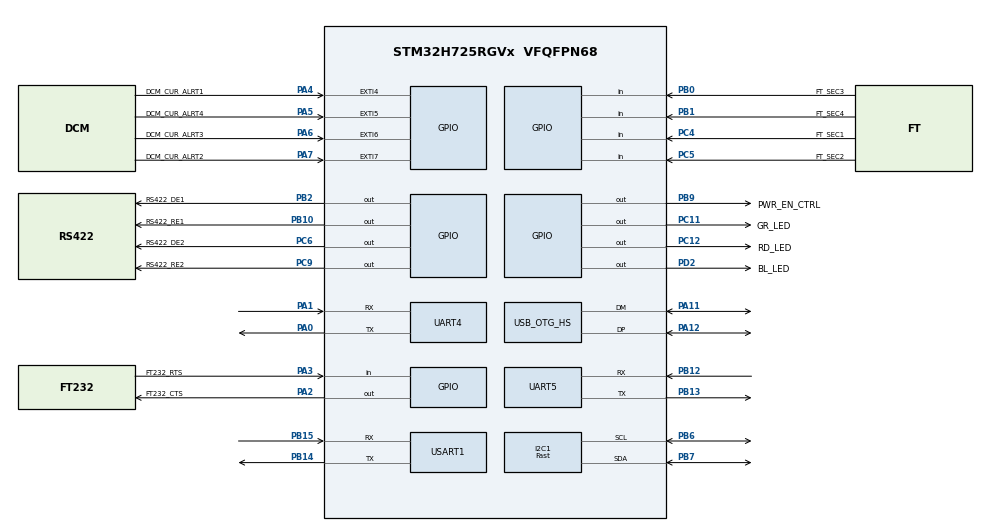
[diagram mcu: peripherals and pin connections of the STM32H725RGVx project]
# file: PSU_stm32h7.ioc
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CORTEX_M7.CPU_DCache=Disabled
CORTEX_M7.CPU_ICache=Enabled
CORTEX_M7.default_mode_Activation=1
Dma.I2C1_RX.0.Direction=DMA_PERIPH_TO_MEMORY
Dma.I2C1_RX.0.EventEnable=DISABLE
Dma.I2C1_RX.0.FIFOMode=DMA_FIFOMODE_DISABLE
Dma.I2C1_RX.0.Instance=DMA1_Stream0
Dma.I2C1_RX.0.MemDataAlignment=DMA_MDATAALIGN_BYTE
Dma.I2C1_RX.0.MemInc=DMA_MINC_ENABLE
Dma.I2C1_RX.0.Mode=DMA_NORMAL
Dma.I2C1_RX.0.PeriphDataAlignment=DMA_PDATAALIGN_BYTE
Dma.I2C1_RX.0.PeriphInc=DMA_PINC_DISABLE
Dma.I2C1_RX.0.Polarity=HAL_DMAMUX_REQ_GEN_RISING
Dma.I2C1_RX.0.Priority=DMA_PRIORITY_MEDIUM
Dma.I2C1_RX.0.RequestNumber=1
Dma.I2C1_RX.0.SignalID=NONE
Dma.I2C1_RX.0.SyncEnable=DISABLE
Dma.I2C1_RX.0.SyncPolarity=HAL_DMAMUX_SYNC_NO_EVENT
Dma.I2C1_RX.0.SyncRequestNumber=1
Dma.I2C1_RX.0.SyncSignalID=NONE
Dma.I2C1_TX.1.Direction=DMA_MEMORY_TO_PERIPH
Dma.I2C1_TX.1.EventEnable=DISABLE
Dma.I2C1_TX.1.FIFOMode=DMA_FIFOMODE_DISABLE
Dma.I2C1_TX.1.Instance=DMA1_Stream1
Dma.I2C1_TX.1.MemDataAlignment=DMA_MDATAALIGN_BYTE
Dma.I2C1_TX.1.MemInc=DMA_MINC_ENABLE
Dma.I2C1_TX.1.Mode=DMA_NORMAL
Dma.I2C1_TX.1.PeriphDataAlignment=DMA_PDATAALIGN_BYTE
Dma.I2C1_TX.1.PeriphInc=DMA_PINC_DISABLE
Dma.I2C1_TX.1.Polarity=HAL_DMAMUX_REQ_GEN_RISING
Dma.I2C1_TX.1.Priority=DMA_PRIORITY_MEDIUM
Dma.I2C1_TX.1.RequestNumber=1
Dma.I2C1_TX.1.SignalID=NONE
Dma.I2C1_TX.1.SyncEnable=DISABLE
Dma.I2C1_TX.1.SyncPolarity=HAL_DMAMUX_SYNC_NO_EVENT
Dma.I2C1_TX.1.SyncRequestNumber=1
Dma.I2C1_TX.1.SyncSignalID=NONE
Dma.Request0=I2C1_RX
Dma.Request1=I2C1_TX
Dma.Request2=USART1_TX
Dma.Request3=UART5_TX
Dma.Request4=UART4_TX
Dma.Request5=USART1_RX
Dma.Request6=UART4_RX
Dma.Request7=UART5_RX
Dma.UART4_RX.6.Direction=DMA_PERIPH_TO_MEMORY
Dma.UART4_RX.6.EventEnable=DISABLE
Dma.UART4_RX.6.FIFOMode=DMA_FIFOMODE_DISABLE
Dma.UART4_RX.6.Instance=DMA1_Stream6
Dma.UART4_RX.6.MemDataAlignment=DMA_MDATAALIGN_BYTE
Dma.UART4_RX.6.MemInc=DMA_MINC_ENABLE
Dma.UART4_RX.6.Mode=DMA_CIRCULAR
Dma.UART4_RX.6.PeriphDataAlignment=DMA_PDATAALIGN_BYTE
Dma.UART4_RX.6.PeriphInc=DMA_PINC_DISABLE
Dma.UART4_RX.6.Polarity=HAL_DMAMUX_REQ_GEN_RISING
Dma.UART4_RX.6.Priority=DMA_PRIORITY_LOW
Dma.UART4_RX.6.RequestNumber=1
Dma.UART4_RX.6.SignalID=NONE
Dma.UART4_RX.6.SyncEnable=DISABLE
Dma.UART4_RX.6.SyncPolarity=HAL_DMAMUX_SYNC_NO_EVENT
Dma.UART4_RX.6.SyncRequestNumber=1
Dma.UART4_RX.6.SyncSignalID=NONE
Dma.UART4_TX.4.Direction=DMA_MEMORY_TO_PERIPH
Dma.UART4_TX.4.EventEnable=DISABLE
Dma.UART4_TX.4.FIFOMode=DMA_FIFOMODE_DISABLE
Dma.UART4_TX.4.Instance=DMA1_Stream4
Dma.UART4_TX.4.MemDataAlignment=DMA_MDATAALIGN_BYTE
Dma.UART4_TX.4.MemInc=DMA_MINC_ENABLE
Dma.UART4_TX.4.Mode=DMA_NORMAL
Dma.UART4_TX.4.PeriphDataAlignment=DMA_PDATAALIGN_BYTE
Dma.UART4_TX.4.PeriphInc=DMA_PINC_DISABLE
Dma.UART4_TX.4.Polarity=HAL_DMAMUX_REQ_GEN_RISING
Dma.UART4_TX.4.Priority=DMA_PRIORITY_LOW
Dma.UART4_TX.4.RequestNumber=1
Dma.UART4_TX.4.SignalID=NONE
Dma.UART4_TX.4.SyncEnable=DISABLE
Dma.UART4_TX.4.SyncPolarity=HAL_DMAMUX_SYNC_NO_EVENT
Dma.UART4_TX.4.SyncRequestNumber=1
Dma.UART4_TX.4.SyncSignalID=NONE
Dma.UART5_RX.7.Direction=DMA_PERIPH_TO_MEMORY
Dma.UART5_RX.7.EventEnable=DISABLE
Dma.UART5_RX.7.FIFOMode=DMA_FIFOMODE_DISABLE
Dma.UART5_RX.7.Instance=DMA1_Stream7
Dma.UART5_RX.7.MemDataAlignment=DMA_MDATAALIGN_BYTE
Dma.UART5_RX.7.MemInc=DMA_MINC_ENABLE
Dma.UART5_RX.7.Mode=DMA_CIRCULAR
Dma.UART5_RX.7.PeriphDataAlignment=DMA_PDATAALIGN_BYTE
Dma.UART5_RX.7.PeriphInc=DMA_PINC_DISABLE
Dma.UART5_RX.7.Polarity=HAL_DMAMUX_REQ_GEN_RISING
Dma.UART5_RX.7.Priority=DMA_PRIORITY_LOW
Dma.UART5_RX.7.RequestNumber=1
Dma.UART5_RX.7.SignalID=NONE
Dma.UART5_RX.7.SyncEnable=DISABLE
Dma.UART5_RX.7.SyncPolarity=HAL_DMAMUX_SYNC_NO_EVENT
Dma.UART5_RX.7.SyncRequestNumber=1
Dma.UART5_RX.7.SyncSignalID=NONE
Dma.UART5_TX.3.Direction=DMA_MEMORY_TO_PERIPH
Dma.UART5_TX.3.EventEnable=DISABLE
Dma.UART5_TX.3.FIFOMode=DMA_FIFOMODE_DISABLE
Dma.UART5_TX.3.Instance=DMA1_Stream3
Dma.UART5_TX.3.MemDataAlignment=DMA_MDATAALIGN_BYTE
Dma.UART5_TX.3.MemInc=DMA_MINC_ENABLE
Dma.UART5_TX.3.Mode=DMA_NORMAL
Dma.UART5_TX.3.PeriphDataAlignment=DMA_PDATAALIGN_BYTE
Dma.UART5_TX.3.PeriphInc=DMA_PINC_DISABLE
Dma.UART5_TX.3.Polarity=HAL_DMAMUX_REQ_GEN_RISING
Dma.UART5_TX.3.Priority=DMA_PRIORITY_LOW
Dma.UART5_TX.3.RequestNumber=1
Dma.UART5_TX.3.SignalID=NONE
Dma.UART5_TX.3.SyncEnable=DISABLE
Dma.UART5_TX.3.SyncPolarity=HAL_DMAMUX_SYNC_NO_EVENT
Dma.UART5_TX.3.SyncRequestNumber=1
Dma.UART5_TX.3.SyncSignalID=NONE
Dma.USART1_RX.5.Direction=DMA_PERIPH_TO_MEMORY
Dma.USART1_RX.5.EventEnable=DISABLE
Dma.USART1_RX.5.FIFOMode=DMA_FIFOMODE_DISABLE
Dma.USART1_RX.5.Instance=DMA1_Stream5
Dma.USART1_RX.5.MemDataAlignment=DMA_MDATAALIGN_BYTE
Dma.USART1_RX.5.MemInc=DMA_MINC_ENABLE
Dma.USART1_RX.5.Mode=DMA_CIRCULAR
Dma.USART1_RX.5.PeriphDataAlignment=DMA_PDATAALIGN_BYTE
Dma.USART1_RX.5.PeriphInc=DMA_PINC_DISABLE
Dma.USART1_RX.5.Polarity=HAL_DMAMUX_REQ_GEN_RISING
Dma.USART1_RX.5.Priority=DMA_PRIORITY_LOW
Dma.USART1_RX.5.RequestNumber=1
Dma.USART1_RX.5.SignalID=NONE
Dma.USART1_RX.5.SyncEnable=DISABLE
Dma.USART1_RX.5.SyncPolarity=HAL_DMAMUX_SYNC_NO_EVENT
Dma.USART1_RX.5.SyncRequestNumber=1
Dma.USART1_RX.5.SyncSignalID=NONE
Dma.USART1_TX.2.Direction=DMA_MEMORY_TO_PERIPH
Dma.USART1_TX.2.EventEnable=DISABLE
Dma.USART1_TX.2.FIFOMode=DMA_FIFOMODE_DISABLE
Dma.USART1_TX.2.Instance=DMA1_Stream2
Dma.USART1_TX.2.MemDataAlignment=DMA_MDATAALIGN_BYTE
Dma.USART1_TX.2.MemInc=DMA_MINC_ENABLE
Dma.USART1_TX.2.Mode=DMA_NORMAL
Dma.USART1_TX.2.PeriphDataAlignment=DMA_PDATAALIGN_BYTE
Dma.USART1_TX.2.PeriphInc=DMA_PINC_DISABLE
Dma.USART1_TX.2.Polarity=HAL_DMAMUX_REQ_GEN_RISING
Dma.USART1_TX.2.Priority=DMA_PRIORITY_LOW
Dma.USART1_TX.2.RequestNumber=1
Dma.USART1_TX.2.SignalID=NONE
Dma.USART1_TX.2.SyncEnable=DISABLE
Dma.USART1_TX.2.SyncPolarity=HAL_DMAMUX_SYNC_NO_EVENT
Dma.USART1_TX.2.SyncRequestNumber=1
Dma.USART1_TX.2.SyncSignalID=NONE
I2C1.I2C_Coeff_DF=2
I2C1.I2C_Fall_Time=10
I2C1.I2C_Rise_Time=100
I2C1.I2C_Speed_Mode=I2C_Fast
I2C1.Timing=0x00C01F6A
Mcu.Family=STM32H7
Mcu.Name=STM32H725RGVx
Mcu.Package=VFQFPN68
NVIC.DMA1_Stream0_IRQn=true\:3\:0\:true\:false\:true\:false\:true\:true
NVIC.DMA1_Stream1_IRQn=true\:3\:0\:true\:false\:true\:false\:true\:true
NVIC.DMA1_Stream2_IRQn=true\:5\:0\:true\:false\:true\:false\:true\:true
NVIC.DMA1_Stream3_IRQn=true\:5\:0\:true\:false\:true\:false\:true\:true
NVIC.DMA1_Stream4_IRQn=true\:5\:0\:true\:false\:true\:false\:true\:true
NVIC.DMA1_Stream5_IRQn=true\:6\:0\:true\:false\:true\:false\:true\:true
NVIC.DMA1_Stream6_IRQn=true\:6\:0\:true\:false\:true\:false\:true\:true
NVIC.DMA1_Stream7_IRQn=true\:6\:0\:true\:false\:true\:false\:true\:true
NVIC.EXTI4_IRQn=true\:4\:0\:true\:false\:true\:true\:true\:true
NVIC.EXTI9_5_IRQn=true\:4\:0\:true\:false\:true\:true\:true\:true
NVIC.I2C1_ER_IRQn=true\:3\:0\:true\:false\:true\:true\:true\:true
NVIC.I2C1_EV_IRQn=true\:3\:0\:true\:false\:true\:true\:true\:true
NVIC.OTG_HS_IRQn=true\:6\:0\:true\:false\:true\:false\:true\:true
NVIC.PriorityGroup=NVIC_PRIORITYGROUP_4
NVIC.UART4_IRQn=true\:5\:0\:true\:false\:true\:false\:true\:true
NVIC.UART5_IRQn=true\:5\:0\:true\:false\:true\:false\:true\:true
NVIC.USART1_IRQn=true\:5\:0\:true\:false\:true\:false\:true\:true
PA0.Mode=Asynchronous
PA0.Signal=UART4_TX
PA1.Mode=Asynchronous
PA1.Signal=UART4_RX
PA11.Mode=Device_Only_FS
PA11.Signal=USB_OTG_HS_DM
PA12.Mode=Device_Only_FS
PA12.Signal=USB_OTG_HS_DP
PA13(JTMS/SWDIO).Mode=Serial_Wire
PA13(JTMS/SWDIO).Signal=DEBUG_JTMS-SWDIO
PA14(JTCK/SWCLK).Mode=Serial_Wire
PA14(JTCK/SWCLK).Signal=DEBUG_JTCK-SWCLK
PA2.GPIO_Label=FT232_CTS
PA2.Signal=GPIO_Output
PA3.GPIO_Label=FT232_RTS
PA3.GPIO_PuPd=GPIO_PULLUP
PA3.Signal=GPIO_Input
PA4.GPIO_Label=DCM_CUR_ALRT1
PA4.GPIO_ModeDefaultEXTI=GPIO_MODE_IT_FALLING
PA4.GPIO_PuPd=GPIO_PULLUP
PA4.Signal=GPXTI4
PA5.GPIO_Label=DCM_CUR_ALRT4
PA5.GPIO_ModeDefaultEXTI=GPIO_MODE_IT_FALLING
PA5.GPIO_PuPd=GPIO_PULLUP
PA5.Signal=GPXTI5
PA6.GPIO_Label=DCM_CUR_ALRT3
PA6.GPIO_ModeDefaultEXTI=GPIO_MODE_IT_FALLING
PA6.GPIO_PuPd=GPIO_PULLUP
PA6.Signal=GPXTI6
PA7.GPIO_Label=DCM_CUR_ALRT2
PA7.GPIO_ModeDefaultEXTI=GPIO_MODE_IT_FALLING
PA7.GPIO_PuPd=GPIO_PULLUP
PA7.Signal=GPXTI7
PB0.GPIO_Label=FT_SEC3
PB0.Signal=GPIO_Input
PB1.GPIO_Label=FT_SEC4
PB1.Signal=GPIO_Input
PB10.GPIO_Label=RS422_RE1
PB10.GPIO_ModeDefaultOutputPP=GPIO_MODE_OUTPUT_PP
PB10.GPIO_PuPd=GPIO_NOPULL
PB10.Signal=GPIO_Output
PB12.Mode=Asynchronous
PB12.Signal=UART5_RX
PB13.Mode=Asynchronous
PB13.Signal=UART5_TX
PB14.Mode=Asynchronous
PB14.Signal=USART1_TX
PB15.Mode=Asynchronous
PB15.Signal=USART1_RX
PB2.GPIO_Label=RS422_DE1
PB2.Signal=GPIO_Output
PB6.Mode=I2C
PB6.Signal=I2C1_SCL
PB7.Mode=I2C
PB7.Signal=I2C1_SDA
PB9.GPIO_Label=PWR_EN_CTRL
PB9.Signal=GPIO_Output
PC11.GPIO_Label=GR_LED
PC11.Signal=GPIO_Output
PC12.GPIO_Label=RD_LED
PC12.Signal=GPIO_Output
PC14-OSC32_IN.Mode=LSE-External-Oscillator
PC14-OSC32_IN.Signal=RCC_OSC32_IN
PC15-OSC32_OUT.Mode=LSE-External-Oscillator
PC15-OSC32_OUT.Signal=RCC_OSC32_OUT
PC4.GPIO_Label=FT_SEC1
PC4.Signal=GPIO_Input
PC5.GPIO_Label=FT_SEC2
PC5.Signal=GPIO_Input
PC6.GPIO_Label=RS422_DE2
PC6.Signal=GPIO_Output
PC9.GPIO_Label=RS422_RE2
PC9.Signal=GPIO_Output
PD2.GPIO_Label=BL_LED
PD2.Signal=GPIO_Output
PH0-OSC_IN.Mode=HSE-External-Clock-Source
PH0-OSC_IN.Signal=RCC_OSC_IN
ProjectManager.HeapSize=0x200
ProjectManager.StackSize=0x400
ProjectManager.TargetToolchain=STM32CubeIDE
RCC.ADCFreq_Value=50390625
RCC.APB1Freq_Value=50000000
RCC.APB2Freq_Value=50000000
RCC.APB3Freq_Value=50000000
RCC.APB4Freq_Value=50000000
RCC.CortexFreq_Value=200000000
RCC.D1PPRE=RCC_APB3_DIV2
RCC.D2PPRE1=RCC_APB1_DIV2
RCC.D2PPRE2=RCC_APB2_DIV2
RCC.D3PPRE=RCC_APB4_DIV2
RCC.DIVM1=5
RCC.DIVN1=40
RCC.DIVP1=1
RCC.DIVQ1=5
RCC.DIVR1=5
RCC.HCLKFreq_Value=100000000
RCC.HPRE=RCC_HCLK_DIV2
RCC.I2C123CLockSelection=RCC_I2C1235CLKSOURCE_HSI
RCC.PLLFRACN=0
RCC.PLLSourceVirtual=RCC_PLLSOURCE_HSE
RCC.SYSCLKFreq_VALUE=200000000
RCC.SYSCLKSource=RCC_SYSCLKSOURCE_PLLCLK
RCC.USBCLockSelection=RCC_USBCLKSOURCE_HSI48
RCC.USBFreq_Value=48000000
USART1.VirtualMode-Asynchronous=VM_ASYNC
USB_DEVICE.CLASS_NAME_HS=CDC
USB_DEVICE.VirtualMode=Cdc
USB_DEVICE.VirtualModeHS=Cdc_HS
USB_OTG_HS.VirtualMode=Device_Only_FS
VP_MEMORYMAP_VS_MEMORYMAP.Mode=CurAppReg
VP_USB_DEVICE_VS_USB_DEVICE_CDC_HS.Mode=CDC_HS
board=custom

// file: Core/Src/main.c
/* USER CODE BEGIN Header */
/**
  ******************************************************************************
  * @file           : main.c
  * @brief          : Main program body
  ******************************************************************************
  * @attention
  *
  * Copyright (c) 2026 STMicroelectronics.
  * All rights reserved.
  *
  * This software is licensed under terms that can be found in the LICENSE file
  * in the root directory of this software component.
  * If no LICENSE file comes with this software, it is provided AS-IS.
  *
  ******************************************************************************
  */
/* USER CODE END Header */
#include "main.h"
#include "usb_device.h"

/* USER CODE BEGIN Includes */
#include "app_main.h"
#include "safety.h"
/* USER CODE END Includes */

I2C_HandleTypeDef hi2c1;
DMA_HandleTypeDef hdma_i2c1_rx;
DMA_HandleTypeDef hdma_i2c1_tx;

UART_HandleTypeDef huart4;
UART_HandleTypeDef huart5;
UART_HandleTypeDef huart1;
DMA_HandleTypeDef hdma_uart4_tx;
DMA_HandleTypeDef hdma_uart4_rx;
DMA_HandleTypeDef hdma_uart5_tx;
DMA_HandleTypeDef hdma_uart5_rx;
DMA_HandleTypeDef hdma_usart1_tx;
DMA_HandleTypeDef hdma_usart1_rx;

void SystemClock_Config(void);
static void MPU_Config(void);
static void MX_GPIO_Init(void);
static void MX_DMA_Init(void);
static void MX_UART4_Init(void);
static void MX_I2C1_Init(void);
static void MX_UART5_Init(void);
static void MX_USART1_UART_Init(void);

int main(void)
{

  /* USER CODE BEGIN 1 */
	__enable_irq();

	  extern uint32_t g_pfnVectors;
	  SCB->VTOR = (uint32_t)&g_pfnVectors;
	  __DSB();
	  __ISB();
  /* USER CODE END 1 */

  /* MPU Configuration--------------------------------------------------------*/
  MPU_Config();

  /* Enable the CPU Cache */

  /* Enable I-Cache---------------------------------------------------------*/
  SCB_EnableICache();

  /* MCU Configuration--------------------------------------------------------*/

  /* Reset of all peripherals, Initializes the Flash interface and the Systick. */
  HAL_Init();

  /* USER CODE BEGIN Init */

  // Enable clock cho vung D2 SRAM
  __HAL_RCC_D2SRAM1_CLK_ENABLE();
  __HAL_RCC_D2SRAM2_CLK_ENABLE();

  /* USER CODE END Init */

  /* Configure the system clock */
  SystemClock_Config();

  /* USER CODE BEGIN SysInit */

  App_EarlyInit();

  /* USER CODE END SysInit */

  /* Initialize all configured peripherals */
  MX_GPIO_Init();
  MX_DMA_Init();
  MX_UART4_Init();
  MX_I2C1_Init();
  MX_UART5_Init();
  MX_USART1_UART_Init();
  MX_USB_DEVICE_Init();
  /* USER CODE BEGIN 2 */

  App_Init();

  /* USER CODE END 2 */

  /* Infinite loop */
  /* USER CODE BEGIN WHILE */
  while (1)
  {

	  App_Loop();

    /* USER CODE END WHILE */

  }
}

void SystemClock_Config(void)
{
  RCC_OscInitTypeDef RCC_OscInitStruct = {0};
  RCC_ClkInitTypeDef RCC_ClkInitStruct = {0};

  /** Supply configuration update enable
  */
  HAL_PWREx_ConfigSupply(PWR_DIRECT_SMPS_SUPPLY);

  /** Configure the main internal regulator output voltage
  */
  __HAL_PWR_VOLTAGESCALING_CONFIG(PWR_REGULATOR_VOLTAGE_SCALE2);

  while(!__HAL_PWR_GET_FLAG(PWR_FLAG_VOSRDY)) {}

  /** Initializes the RCC Oscillators according to the specified parameters
  * in the RCC_OscInitTypeDef structure.
  */
  RCC_OscInitStruct.OscillatorType = RCC_OSCILLATORTYPE_HSI48|RCC_OSCILLATORTYPE_HSI
                              |RCC_OSCILLATORTYPE_HSE;
  RCC_OscInitStruct.HSEState = RCC_HSE_BYPASS;
  RCC_OscInitStruct.HSIState = RCC_HSI_DIV1;
  RCC_OscInitStruct.HSICalibrationValue = 64;
  RCC_OscInitStruct.HSI48State = RCC_HSI48_ON;
  RCC_OscInitStruct.PLL.PLLState = RCC_PLL_ON;
  RCC_OscInitStruct.PLL.PLLSource = RCC_PLLSOURCE_HSE;
  RCC_OscInitStruct.PLL.PLLM = 5;
  RCC_OscInitStruct.PLL.PLLN = 40;
  RCC_OscInitStruct.PLL.PLLP = 1;
  RCC_OscInitStruct.PLL.PLLQ = 5;
  RCC_OscInitStruct.PLL.PLLR = 5;
  RCC_OscInitStruct.PLL.PLLRGE = RCC_PLL1VCIRANGE_2;
  RCC_OscInitStruct.PLL.PLLVCOSEL = RCC_PLL1VCOWIDE;
  RCC_OscInitStruct.PLL.PLLFRACN = 0;
  if (HAL_RCC_OscConfig(&RCC_OscInitStruct) != HAL_OK)
  {
    Error_Handler();
  }

  /** Initializes the CPU, AHB and APB buses clocks
  */
  RCC_ClkInitStruct.ClockType = RCC_CLOCKTYPE_HCLK|RCC_CLOCKTYPE_SYSCLK
                              |RCC_CLOCKTYPE_PCLK1|RCC_CLOCKTYPE_PCLK2
                              |RCC_CLOCKTYPE_D3PCLK1|RCC_CLOCKTYPE_D1PCLK1;
  RCC_ClkInitStruct.SYSCLKSource = RCC_SYSCLKSOURCE_PLLCLK;
  RCC_ClkInitStruct.SYSCLKDivider = RCC_SYSCLK_DIV1;
  RCC_ClkInitStruct.AHBCLKDivider = RCC_HCLK_DIV2;
  RCC_ClkInitStruct.APB3CLKDivider = RCC_APB3_DIV2;
  RCC_ClkInitStruct.APB1CLKDivider = RCC_APB1_DIV2;
  RCC_ClkInitStruct.APB2CLKDivider = RCC_APB2_DIV2;
  RCC_ClkInitStruct.APB4CLKDivider = RCC_APB4_DIV2;

  if (HAL_RCC_ClockConfig(&RCC_ClkInitStruct, FLASH_LATENCY_1) != HAL_OK)
  {
    Error_Handler();
  }
}

static void MX_I2C1_Init(void)
{

  hi2c1.Instance = I2C1;
  hi2c1.Init.Timing = 0x00C01F6A;
  hi2c1.Init.OwnAddress1 = 0;
  hi2c1.Init.AddressingMode = I2C_ADDRESSINGMODE_7BIT;
  hi2c1.Init.DualAddressMode = I2C_DUALADDRESS_DISABLE;
  hi2c1.Init.OwnAddress2 = 0;
  hi2c1.Init.OwnAddress2Masks = I2C_OA2_NOMASK;
  hi2c1.Init.GeneralCallMode = I2C_GENERALCALL_DISABLE;
  hi2c1.Init.NoStretchMode = I2C_NOSTRETCH_DISABLE;
  if (HAL_I2C_Init(&hi2c1) != HAL_OK)
  {
    Error_Handler();
  }

  /** Configure Analogue filter
  */
  if (HAL_I2CEx_ConfigAnalogFilter(&hi2c1, I2C_ANALOGFILTER_ENABLE) != HAL_OK)
  {
    Error_Handler();
  }

  /** Configure Digital filter
  */
  if (HAL_I2CEx_ConfigDigitalFilter(&hi2c1, 2) != HAL_OK)
  {
    Error_Handler();
  }

}

static void MX_UART4_Init(void)
{

  huart4.Instance = UART4;
  huart4.Init.BaudRate = 115200;
  huart4.Init.WordLength = UART_WORDLENGTH_8B;
  huart4.Init.StopBits = UART_STOPBITS_1;
  huart4.Init.Parity = UART_PARITY_NONE;
  huart4.Init.Mode = UART_MODE_TX_RX;
  huart4.Init.HwFlowCtl = UART_HWCONTROL_NONE;
  huart4.Init.OverSampling = UART_OVERSAMPLING_16;
  huart4.Init.OneBitSampling = UART_ONE_BIT_SAMPLE_DISABLE;
  huart4.Init.ClockPrescaler = UART_PRESCALER_DIV1;
  huart4.AdvancedInit.AdvFeatureInit = UART_ADVFEATURE_NO_INIT;
  if (HAL_UART_Init(&huart4) != HAL_OK)
  {
    Error_Handler();
  }
  if (HAL_UARTEx_SetTxFifoThreshold(&huart4, UART_TXFIFO_THRESHOLD_1_8) != HAL_OK)
  {
    Error_Handler();
  }
  if (HAL_UARTEx_SetRxFifoThreshold(&huart4, UART_RXFIFO_THRESHOLD_1_8) != HAL_OK)
  {
    Error_Handler();
  }
  if (HAL_UARTEx_DisableFifoMode(&huart4) != HAL_OK)
  {
    Error_Handler();
  }

}

static void MX_UART5_Init(void)
{

  huart5.Instance = UART5;
  huart5.Init.BaudRate = 115200;
  huart5.Init.WordLength = UART_WORDLENGTH_8B;
  huart5.Init.StopBits = UART_STOPBITS_1;
  huart5.Init.Parity = UART_PARITY_NONE;
  huart5.Init.Mode = UART_MODE_TX_RX;
  huart5.Init.HwFlowCtl = UART_HWCONTROL_NONE;
  huart5.Init.OverSampling = UART_OVERSAMPLING_16;
  huart5.Init.OneBitSampling = UART_ONE_BIT_SAMPLE_DISABLE;
  huart5.Init.ClockPrescaler = UART_PRESCALER_DIV1;
  huart5.AdvancedInit.AdvFeatureInit = UART_ADVFEATURE_NO_INIT;
  if (HAL_UART_Init(&huart5) != HAL_OK)
  {
    Error_Handler();
  }
  if (HAL_UARTEx_SetTxFifoThreshold(&huart5, UART_TXFIFO_THRESHOLD_1_8) != HAL_OK)
  {
    Error_Handler();
  }
  if (HAL_UARTEx_SetRxFifoThreshold(&huart5, UART_RXFIFO_THRESHOLD_1_8) != HAL_OK)
  {
    Error_Handler();
  }
  if (HAL_UARTEx_DisableFifoMode(&huart5) != HAL_OK)
  {
    Error_Handler();
  }

}

static void MX_USART1_UART_Init(void)
{

  huart1.Instance = USART1;
  huart1.Init.BaudRate = 115200;
  huart1.Init.WordLength = UART_WORDLENGTH_8B;
  huart1.Init.StopBits = UART_STOPBITS_1;
  huart1.Init.Parity = UART_PARITY_NONE;
  huart1.Init.Mode = UART_MODE_TX_RX;
  huart1.Init.HwFlowCtl = UART_HWCONTROL_NONE;
  huart1.Init.OverSampling = UART_OVERSAMPLING_16;
  huart1.Init.OneBitSampling = UART_ONE_BIT_SAMPLE_DISABLE;
  huart1.Init.ClockPrescaler = UART_PRESCALER_DIV1;
  huart1.AdvancedInit.AdvFeatureInit = UART_ADVFEATURE_NO_INIT;
  if (HAL_UART_Init(&huart1) != HAL_OK)
  {
    Error_Handler();
  }
  if (HAL_UARTEx_SetTxFifoThreshold(&huart1, UART_TXFIFO_THRESHOLD_1_8) != HAL_OK)
  {
    Error_Handler();
  }
  if (HAL_UARTEx_SetRxFifoThreshold(&huart1, UART_RXFIFO_THRESHOLD_1_8) != HAL_OK)
  {
    Error_Handler();
  }
  if (HAL_UARTEx_DisableFifoMode(&huart1) != HAL_OK)
  {
    Error_Handler();
  }

}

static void MX_DMA_Init(void)
{

  /* DMA controller clock enable */
  __HAL_RCC_DMA1_CLK_ENABLE();

  /* DMA interrupt init */
  /* DMA1_Stream0_IRQn interrupt configuration */
  HAL_NVIC_SetPriority(DMA1_Stream0_IRQn, 3, 0);
  HAL_NVIC_EnableIRQ(DMA1_Stream0_IRQn);
  /* DMA1_Stream1_IRQn interrupt configuration */
  HAL_NVIC_SetPriority(DMA1_Stream1_IRQn, 3, 0);
  HAL_NVIC_EnableIRQ(DMA1_Stream1_IRQn);
  /* DMA1_Stream2_IRQn interrupt configuration */
  HAL_NVIC_SetPriority(DMA1_Stream2_IRQn, 5, 0);
  HAL_NVIC_EnableIRQ(DMA1_Stream2_IRQn);
  /* DMA1_Stream3_IRQn interrupt configuration */
  HAL_NVIC_SetPriority(DMA1_Stream3_IRQn, 5, 0);
  HAL_NVIC_EnableIRQ(DMA1_Stream3_IRQn);
  /* DMA1_Stream4_IRQn interrupt configuration */
  HAL_NVIC_SetPriority(DMA1_Stream4_IRQn, 5, 0);
  HAL_NVIC_EnableIRQ(DMA1_Stream4_IRQn);
  /* DMA1_Stream5_IRQn interrupt configuration */
  HAL_NVIC_SetPriority(DMA1_Stream5_IRQn, 6, 0);
  HAL_NVIC_EnableIRQ(DMA1_Stream5_IRQn);
  /* DMA1_Stream6_IRQn interrupt configuration */
  HAL_NVIC_SetPriority(DMA1_Stream6_IRQn, 6, 0);
  HAL_NVIC_EnableIRQ(DMA1_Stream6_IRQn);
  /* DMA1_Stream7_IRQn interrupt configuration */
  HAL_NVIC_SetPriority(DMA1_Stream7_IRQn, 6, 0);
  HAL_NVIC_EnableIRQ(DMA1_Stream7_IRQn);

}

static void MX_GPIO_Init(void)
{
  GPIO_InitTypeDef GPIO_InitStruct = {0};

  /* GPIO Ports Clock Enable */
  __HAL_RCC_GPIOC_CLK_ENABLE();
  __HAL_RCC_GPIOH_CLK_ENABLE();
  __HAL_RCC_GPIOA_CLK_ENABLE();
  __HAL_RCC_GPIOB_CLK_ENABLE();
  __HAL_RCC_GPIOD_CLK_ENABLE();

  /*Configure GPIO pin Output Level */
  HAL_GPIO_WritePin(FT232_CTS_GPIO_Port, FT232_CTS_Pin, GPIO_PIN_RESET);

  /*Configure GPIO pin Output Level */
  HAL_GPIO_WritePin(GPIOB, RS422_DE1_Pin|RS422_RE1_Pin|PWR_EN_CTRL_Pin, GPIO_PIN_RESET);

  /*Configure GPIO pin Output Level */
  HAL_GPIO_WritePin(GPIOC, RS422_DE2_Pin|RS422_RE2_Pin|GR_LED_Pin|RD_LED_Pin, GPIO_PIN_RESET);

  /*Configure GPIO pin Output Level */
  HAL_GPIO_WritePin(BL_LED_GPIO_Port, BL_LED_Pin, GPIO_PIN_RESET);

  /*Configure GPIO pin : FT232_CTS_Pin */
  GPIO_InitStruct.Pin = FT232_CTS_Pin;
  GPIO_InitStruct.Mode = GPIO_MODE_OUTPUT_PP;
  GPIO_InitStruct.Pull = GPIO_NOPULL;
  GPIO_InitStruct.Speed = GPIO_SPEED_FREQ_LOW;
  HAL_GPIO_Init(FT232_CTS_GPIO_Port, &GPIO_InitStruct);

  /*Configure GPIO pin : FT232_RTS_Pin */
  GPIO_InitStruct.Pin = FT232_RTS_Pin;
  GPIO_InitStruct.Mode = GPIO_MODE_INPUT;
  GPIO_InitStruct.Pull = GPIO_PULLUP;
  HAL_GPIO_Init(FT232_RTS_GPIO_Port, &GPIO_InitStruct);

  /*Configure GPIO pins : DCM_CUR_ALRT1_Pin DCM_CUR_ALRT4_Pin DCM_CUR_ALRT3_Pin DCM_CUR_ALRT2_Pin */
  GPIO_InitStruct.Pin = DCM_CUR_ALRT1_Pin|DCM_CUR_ALRT4_Pin|DCM_CUR_ALRT3_Pin|DCM_CUR_ALRT2_Pin;
  GPIO_InitStruct.Mode = GPIO_MODE_IT_FALLING;
  GPIO_InitStruct.Pull = GPIO_PULLUP;
  HAL_GPIO_Init(GPIOA, &GPIO_InitStruct);

  /*Configure GPIO pins : FT_SEC1_Pin FT_SEC2_Pin */
  GPIO_InitStruct.Pin = FT_SEC1_Pin|FT_SEC2_Pin;
  GPIO_InitStruct.Mode = GPIO_MODE_INPUT;
  GPIO_InitStruct.Pull = GPIO_NOPULL;
  HAL_GPIO_Init(GPIOC, &GPIO_InitStruct);

  /*Configure GPIO pins : FT_SEC3_Pin FT_SEC4_Pin */
  GPIO_InitStruct.Pin = FT_SEC3_Pin|FT_SEC4_Pin;
  GPIO_InitStruct.Mode = GPIO_MODE_INPUT;
  GPIO_InitStruct.Pull = GPIO_NOPULL;
  HAL_GPIO_Init(GPIOB, &GPIO_InitStruct);

  /*Configure GPIO pins : RS422_DE1_Pin RS422_RE1_Pin PWR_EN_CTRL_Pin */
  GPIO_InitStruct.Pin = RS422_DE1_Pin|RS422_RE1_Pin|PWR_EN_CTRL_Pin;
  GPIO_InitStruct.Mode = GPIO_MODE_OUTPUT_PP;
  GPIO_InitStruct.Pull = GPIO_NOPULL;
  GPIO_InitStruct.Speed = GPIO_SPEED_FREQ_LOW;
  HAL_GPIO_Init(GPIOB, &GPIO_InitStruct);

  /*Configure GPIO pins : RS422_DE2_Pin RS422_RE2_Pin GR_LED_Pin RD_LED_Pin */
  GPIO_InitStruct.Pin = RS422_DE2_Pin|RS422_RE2_Pin|GR_LED_Pin|RD_LED_Pin;
  GPIO_InitStruct.Mode = GPIO_MODE_OUTPUT_PP;
  GPIO_InitStruct.Pull = GPIO_NOPULL;
  GPIO_InitStruct.Speed = GPIO_SPEED_FREQ_LOW;
  HAL_GPIO_Init(GPIOC, &GPIO_InitStruct);

  /*Configure GPIO pin : BL_LED_Pin */
  GPIO_InitStruct.Pin = BL_LED_Pin;
  GPIO_InitStruct.Mode = GPIO_MODE_OUTPUT_PP;
  GPIO_InitStruct.Pull = GPIO_NOPULL;
  GPIO_InitStruct.Speed = GPIO_SPEED_FREQ_LOW;
  HAL_GPIO_Init(BL_LED_GPIO_Port, &GPIO_InitStruct);

  /* EXTI interrupt init*/
  HAL_NVIC_SetPriority(DCM_CUR_ALRT1_EXTI_IRQn, 4, 0);
  HAL_NVIC_EnableIRQ(DCM_CUR_ALRT1_EXTI_IRQn);

  HAL_NVIC_SetPriority(DCM_CUR_ALRT4_EXTI_IRQn, 4, 0);
  HAL_NVIC_EnableIRQ(DCM_CUR_ALRT4_EXTI_IRQn);

}

 /* MPU Configuration */

void MPU_Config(void)
{
  MPU_Region_InitTypeDef MPU_InitStruct = {0};

  /* Disables the MPU */
  HAL_MPU_Disable();

  /** Initializes and configures the Region and the memory to be protected
  */
  MPU_InitStruct.Enable = MPU_REGION_ENABLE;
  MPU_InitStruct.Number = MPU_REGION_NUMBER0;
  MPU_InitStruct.BaseAddress = 0x0;
  MPU_InitStruct.Size = MPU_REGION_SIZE_4GB;
  MPU_InitStruct.SubRegionDisable = 0x87;
  MPU_InitStruct.TypeExtField = MPU_TEX_LEVEL0;
  MPU_InitStruct.AccessPermission = MPU_REGION_NO_ACCESS;
  MPU_InitStruct.DisableExec = MPU_INSTRUCTION_ACCESS_DISABLE;
  MPU_InitStruct.IsShareable = MPU_ACCESS_SHAREABLE;
  MPU_InitStruct.IsCacheable = MPU_ACCESS_NOT_CACHEABLE;
  MPU_InitStruct.IsBufferable = MPU_ACCESS_NOT_BUFFERABLE;

  HAL_MPU_ConfigRegion(&MPU_InitStruct);
  /* Enables the MPU */
  HAL_MPU_Enable(MPU_PRIVILEGED_DEFAULT);

}

void Error_Handler(void)
{
  /* USER CODE BEGIN Error_Handler_Debug */
  /* User can add his own implementation to report the HAL error return state */
  Safety_ForceOff();
  __disable_irq();
  while (1)
  {
  }
  /* USER CODE END Error_Handler_Debug */
}
